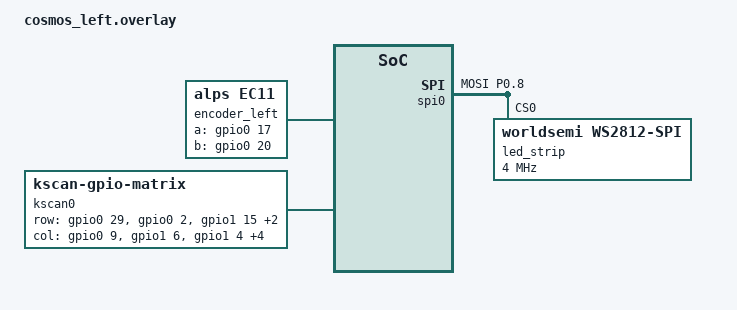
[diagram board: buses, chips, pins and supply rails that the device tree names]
/*
 * Cosmos Keyboard - Left Half
 * Board: nice!nano v2 (nRF52840)
 * Matrix: 5 rows x 7 cols (left side)
 * Split: BLE central (USB host)
 */

#include <dt-bindings/zmk/matrix_transform.h>
#include <dt-bindings/led/led.h>
#include "cosmos.dtsi"

/ {
    chosen {
        zmk,kscan = &kscan0;
        zmk,matrix_transform = &default_transform;
        zmk,sensors = &sensors;
        zmk,underglow = &led_strip;
    };

    sensors: sensors {
        compatible = "zmk,keymap-sensors";
        sensors = <&encoder_left>;
        triggers-per-rotation = <20>;
    };

    encoder_left: encoder_left {
        compatible = "alps,ec11";
        a-gpios = <&gpio0 17 (GPIO_ACTIVE_HIGH | GPIO_PULL_UP)>; 
        b-gpios = <&gpio0 20 (GPIO_ACTIVE_HIGH | GPIO_PULL_UP)>;
        steps = <80>;
    };

    kscan0: kscan {
        compatible = "zmk,kscan-gpio-matrix";
        diode-direction = "col2row";
        #binding-cells = <0>;

        /*
         * nice!nano v2 pinout — Left Half
         * Rows: P0.31, P0.29, P0.02, P1.15, P1.13
         * Cols: P0.22, P0.10, P1.00, P0.11, P1.04, P1.06, P0.09
         */
        row-gpios
            = <&gpio0 29 (GPIO_ACTIVE_HIGH | GPIO_PULL_DOWN)>
            , <&gpio0  2 (GPIO_ACTIVE_HIGH | GPIO_PULL_DOWN)>
            , <&gpio1 15 (GPIO_ACTIVE_HIGH | GPIO_PULL_DOWN)>
            , <&gpio1 13 (GPIO_ACTIVE_HIGH | GPIO_PULL_DOWN)>
            , <&gpio0 31 (GPIO_ACTIVE_HIGH | GPIO_PULL_DOWN)>
            ;

        col-gpios
            = <&gpio0  9 GPIO_ACTIVE_HIGH>
            , <&gpio1  6 GPIO_ACTIVE_HIGH>
            , <&gpio1  4 GPIO_ACTIVE_HIGH>
            , <&gpio0 11 GPIO_ACTIVE_HIGH>
            , <&gpio1  0 GPIO_ACTIVE_HIGH>
            , <&gpio0 24 GPIO_ACTIVE_HIGH>
            , <&gpio0 10 GPIO_ACTIVE_HIGH>
            ;
    };
};


&spi0 {
    compatible = "nordic,nrf-spim";
    status = "okay";
    pinctrl-0 = <&spi0_default>;
    pinctrl-1 = <&spi0_sleep>;
    pinctrl-names = "default", "sleep";

    led_strip: ws2812@0 {
        compatible = "worldsemi,ws2812-spi";
        reg = <0>;
        spi-max-frequency = <4000000>;
        chain-length = <1>;
        spi-one-frame = <0x70>;
        spi-zero-frame = <0x40>;
        color-mapping = <LED_COLOR_ID_GREEN
                         LED_COLOR_ID_RED
                         LED_COLOR_ID_BLUE>;
    };
};

&pinctrl {
    spi0_default: spi0_default {
        group1 {
            psels = <NRF_PSEL(SPIM_MOSI, 0, 8)>; /* P0.08 = D0 */
        };
    };
    spi0_sleep: spi0_sleep {
        group1 {
            psels = <NRF_PSEL(SPIM_MOSI, 0, 8)>;
            low-power-enable;
        };
    };
};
